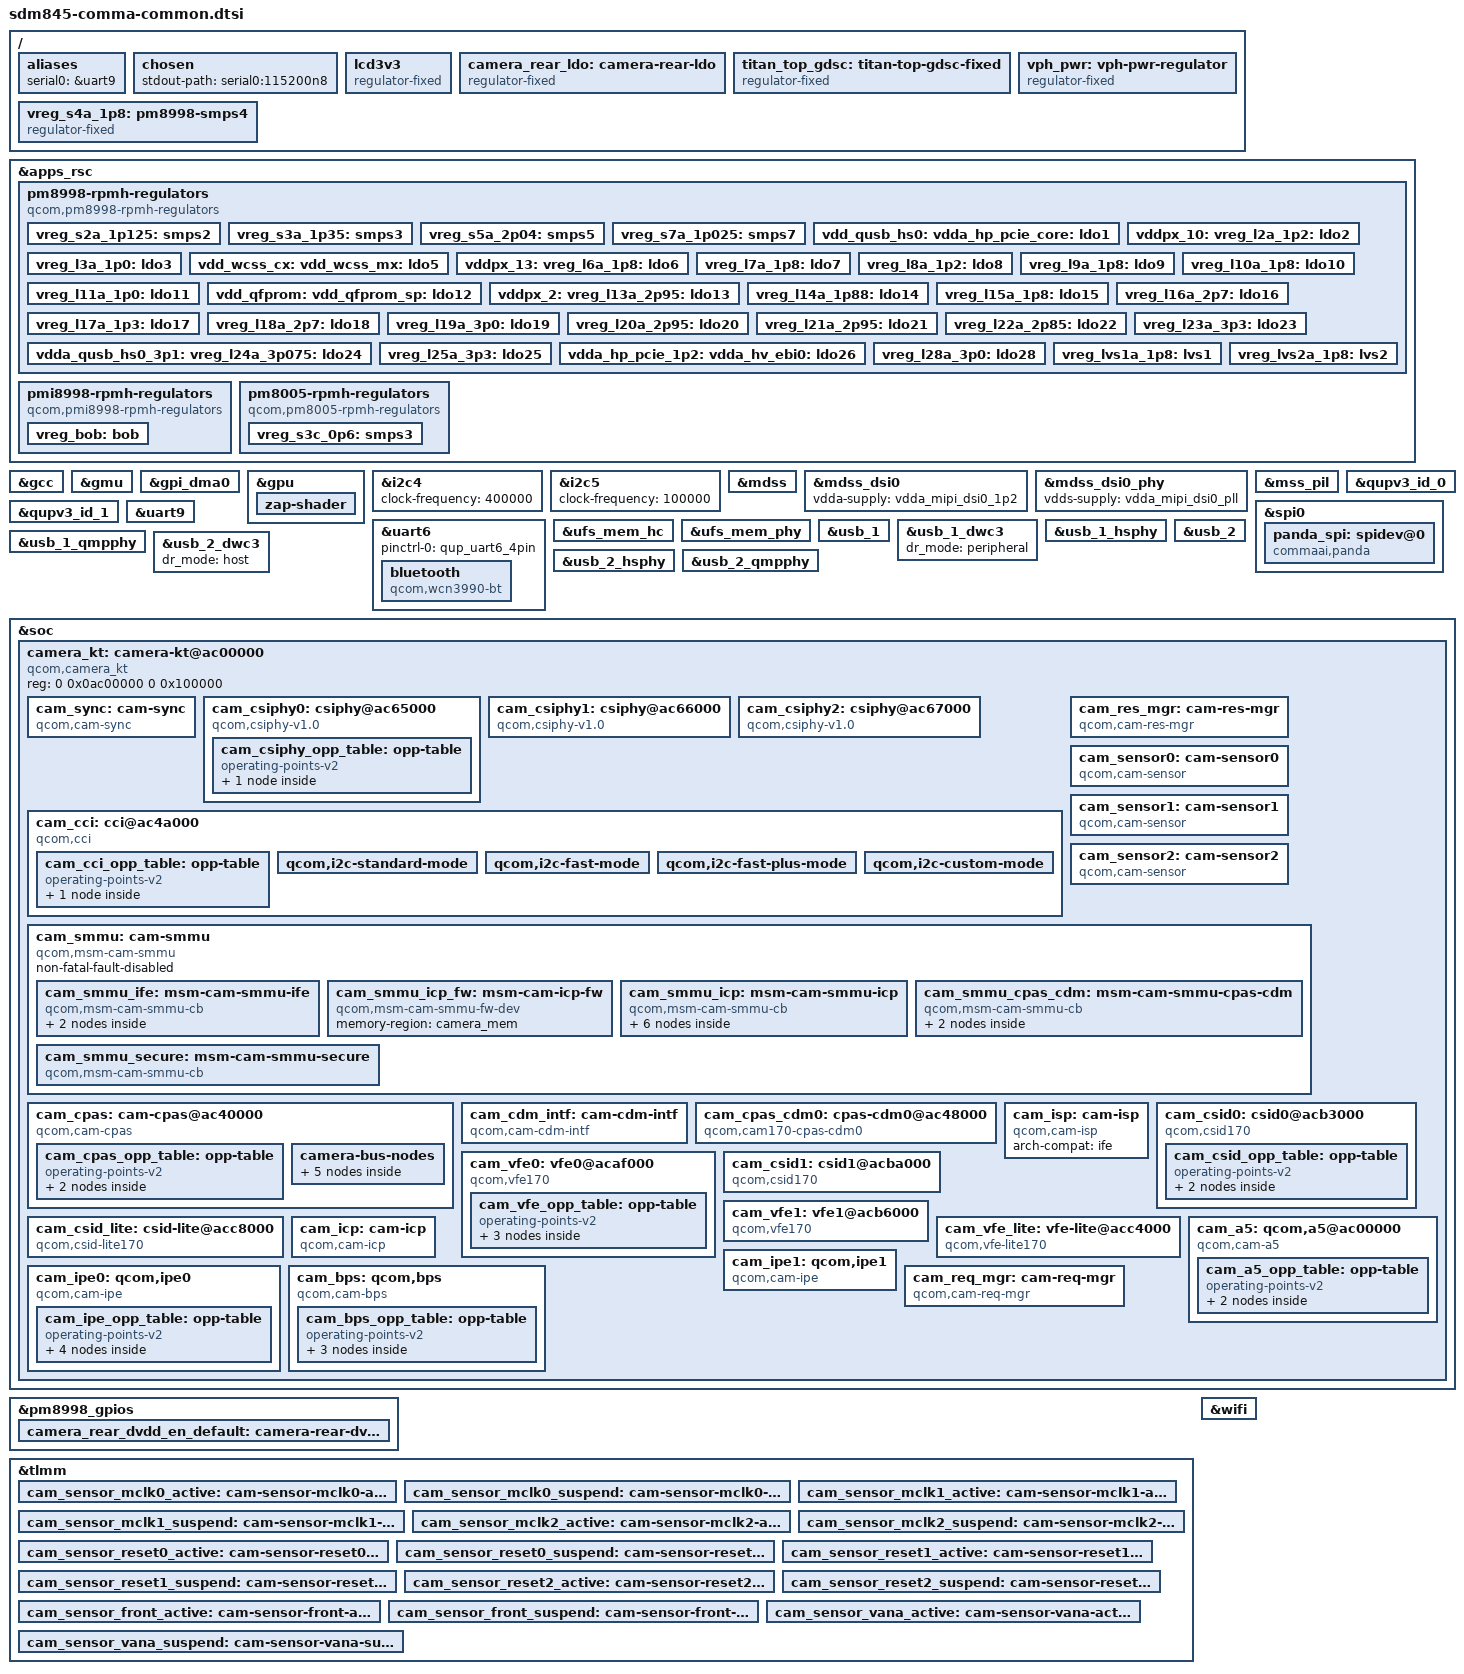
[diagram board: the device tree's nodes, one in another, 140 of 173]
/dts-v1/;

#include <dt-bindings/pinctrl/qcom,pmic-gpio.h>
#include <dt-bindings/regulator/qcom,rpmh-regulator.h>
#include <dt-bindings/power/qcom,rpmhpd.h>
#include "sdm845.dtsi"
#include "pm8998.dtsi"
#include "pmi8998.dtsi"

/ {
	aliases {
		serial0 = &uart9;
	};

	chosen {
		stdout-path = "serial0:115200n8";
	};

	lcd3v3: lcd3v3 {
		compatible = "regulator-fixed";
		regulator-name = "lcd3v3";
		regulator-min-microvolt = <3300000>;
		regulator-max-microvolt = <3300000>;
		gpio = <&pm8998_gpios 13 0>;
		regulator-boot-on;
	};

	camera_rear_ldo: camera-rear-ldo {
		compatible = "regulator-fixed";
		regulator-name = "camera_rear_ldo";
		regulator-min-microvolt = <1050000>;
		regulator-max-microvolt = <1050000>;
		regulator-enable-ramp-delay = <135>;
		gpio = <&pm8998_gpios 12 0>;
		enable-active-high;
		pinctrl-names = "default";
		pinctrl-0 = <&camera_rear_dvdd_en_default>;
	};

	titan_top_gdsc: titan-top-gdsc-fixed {
		compatible = "regulator-fixed";
		regulator-name = "titan_top_gdsc";
		regulator-always-on;
		regulator-boot-on;
	};

	vph_pwr: vph-pwr-regulator {
		compatible = "regulator-fixed";
		regulator-name = "vph_pwr";
		regulator-min-microvolt = <3700000>;
		regulator-max-microvolt = <3700000>;
	};

	/*
	 * Apparently RPMh does not provide support for PM8998 S4 because it
	 * is always-on; model it as a fixed regulator.
	 */
	vreg_s4a_1p8: pm8998-smps4 {
		compatible = "regulator-fixed";
		regulator-name = "vreg_s4a_1p8";

		regulator-min-microvolt = <1800000>;
		regulator-max-microvolt = <1800000>;

		regulator-always-on;
		regulator-boot-on;

		vin-supply = <&vph_pwr>;
	};
};

&apps_rsc {
	pm8998-rpmh-regulators {
		compatible = "qcom,pm8998-rpmh-regulators";
		qcom,pmic-id = "a";

		vdd-s1-supply = <&vph_pwr>;
		vdd-s2-supply = <&vph_pwr>;
		vdd-s3-supply = <&vph_pwr>;
		vdd-s4-supply = <&vph_pwr>;
		vdd-s5-supply = <&vph_pwr>;
		vdd-s6-supply = <&vph_pwr>;
		vdd-s7-supply = <&vph_pwr>;
		vdd-s8-supply = <&vph_pwr>;
		vdd-s9-supply = <&vph_pwr>;
		vdd-s10-supply = <&vph_pwr>;
		vdd-s11-supply = <&vph_pwr>;
		vdd-s12-supply = <&vph_pwr>;
		vdd-s13-supply = <&vph_pwr>;
		vdd-l1-l27-supply = <&vreg_s7a_1p025>;
		vdd-l2-l8-l17-supply = <&vreg_s3a_1p35>;
		vdd-l3-l11-supply = <&vreg_s7a_1p025>;
		vdd-l4-l5-supply = <&vreg_s7a_1p025>;
		vdd-l6-supply = <&vph_pwr>;
		vdd-l7-l12-l14-l15-supply = <&vreg_s5a_2p04>;
		vdd-l9-supply = <&vreg_bob>;
		vdd-l10-l23-l25-supply = <&vreg_bob>;
		vdd-l13-l19-l21-supply = <&vreg_bob>;
		vdd-l16-l28-supply = <&vreg_bob>;
		vdd-l18-l22-supply = <&vreg_bob>;
		vdd-l20-l24-supply = <&vreg_bob>;
		vdd-l26-supply = <&vreg_s3a_1p35>;
		vin-lvs-1-2-supply = <&vreg_s4a_1p8>;

		vreg_s2a_1p125: smps2 {
			regulator-min-microvolt = <1100000>;
			regulator-max-microvolt = <1100000>;
		};

		vreg_s3a_1p35: smps3 {
			regulator-min-microvolt = <1352000>;
			regulator-max-microvolt = <1352000>;
		};

		vreg_s5a_2p04: smps5 {
			regulator-min-microvolt = <1904000>;
			regulator-max-microvolt = <2040000>;
		};

		vreg_s7a_1p025: smps7 {
			regulator-min-microvolt = <900000>;
			regulator-max-microvolt = <1028000>;
		};

		vdd_qusb_hs0:
		vdda_hp_pcie_core:
		vdda_mipi_csi0_0p9:
		vdda_mipi_csi1_0p9:
		vdda_mipi_csi2_0p9:
		vdda_mipi_dsi0_pll:
		vdda_mipi_dsi1_pll:
		vdda_qlink_lv:
		vdda_qlink_lv_ck:
		vdda_qrefs_0p875:
		vdda_pcie_core:
		vdda_pll_cc_ebi01:
		vdda_pll_cc_ebi23:
		vdda_sp_sensor:
		vdda_ufs1_core:
		vdda_ufs2_core:
		vdda_usb1_ss_core:
		vdda_usb2_ss_core:
		vreg_l1a_0p875: ldo1 {
			regulator-min-microvolt = <880000>;
			regulator-max-microvolt = <880000>;
			regulator-initial-mode = <RPMH_REGULATOR_MODE_HPM>;
		};

		vddpx_10:
		vreg_l2a_1p2: ldo2 {
			regulator-min-microvolt = <1200000>;
			regulator-max-microvolt = <1200000>;
			regulator-initial-mode = <RPMH_REGULATOR_MODE_HPM>;
			regulator-always-on;
		};

		vreg_l3a_1p0: ldo3 {
			regulator-min-microvolt = <1000000>;
			regulator-max-microvolt = <1000000>;
			regulator-initial-mode = <RPMH_REGULATOR_MODE_HPM>;
		};

		vdd_wcss_cx:
		vdd_wcss_mx:
		vdda_wcss_pll:
		vreg_l5a_0p8: ldo5 {
			regulator-min-microvolt = <800000>;
			regulator-max-microvolt = <800000>;
			regulator-initial-mode = <RPMH_REGULATOR_MODE_HPM>;
		};

		vddpx_13:
		vreg_l6a_1p8: ldo6 {
			regulator-min-microvolt = <1856000>;
			regulator-max-microvolt = <1856000>;
			regulator-initial-mode = <RPMH_REGULATOR_MODE_HPM>;
		};

		vreg_l7a_1p8: ldo7 {
			regulator-min-microvolt = <1800000>;
			regulator-max-microvolt = <1800000>;
			regulator-initial-mode = <RPMH_REGULATOR_MODE_HPM>;
		};

		vreg_l8a_1p2: ldo8 {
			regulator-min-microvolt = <1200000>;
			regulator-max-microvolt = <1248000>;
			regulator-initial-mode = <RPMH_REGULATOR_MODE_HPM>;
		};

		vreg_l9a_1p8: ldo9 {
			regulator-min-microvolt = <1704000>;
			regulator-max-microvolt = <2928000>;
			regulator-initial-mode = <RPMH_REGULATOR_MODE_HPM>;
		};

		vreg_l10a_1p8: ldo10 {
			regulator-min-microvolt = <1704000>;
			regulator-max-microvolt = <2928000>;
			regulator-initial-mode = <RPMH_REGULATOR_MODE_HPM>;
		};

		vreg_l11a_1p0: ldo11 {
			regulator-min-microvolt = <1000000>;
			regulator-max-microvolt = <1048000>;
			regulator-initial-mode = <RPMH_REGULATOR_MODE_HPM>;
		};

		vdd_qfprom:
		vdd_qfprom_sp:
		vdda_apc1_cs_1p8:
		vdda_gfx_cs_1p8:
		vdda_qrefs_1p8:
		vdda_qusb_hs0_1p8:
		vddpx_11:
		vreg_l12a_1p8: ldo12 {
			regulator-min-microvolt = <1800000>;
			regulator-max-microvolt = <1800000>;
			regulator-initial-mode = <RPMH_REGULATOR_MODE_HPM>;
		};

		vddpx_2:
		vreg_l13a_2p95: ldo13 {
			regulator-min-microvolt = <1800000>;
			regulator-max-microvolt = <2960000>;
			regulator-initial-mode = <RPMH_REGULATOR_MODE_HPM>;
		};

		vreg_l14a_1p88: ldo14 {
			regulator-min-microvolt = <1800000>;
			regulator-max-microvolt = <1800000>;
			regulator-initial-mode = <RPMH_REGULATOR_MODE_HPM>;
		};

		vreg_l15a_1p8: ldo15 {
			regulator-min-microvolt = <1800000>;
			regulator-max-microvolt = <1800000>;
			regulator-initial-mode = <RPMH_REGULATOR_MODE_HPM>;
		};

		vreg_l16a_2p7: ldo16 {
			regulator-min-microvolt = <2704000>;
			regulator-max-microvolt = <2704000>;
			regulator-initial-mode = <RPMH_REGULATOR_MODE_HPM>;
		};

		vreg_l17a_1p3: ldo17 {
			regulator-min-microvolt = <1304000>;
			regulator-max-microvolt = <1304000>;
			regulator-initial-mode = <RPMH_REGULATOR_MODE_HPM>;
		};

		vreg_l18a_2p7: ldo18 {
			regulator-min-microvolt = <2704000>;
			regulator-max-microvolt = <2960000>;
			regulator-initial-mode = <RPMH_REGULATOR_MODE_HPM>;
		};

		vreg_l19a_3p0: ldo19 {
			regulator-min-microvolt = <2856000>;
			regulator-max-microvolt = <3104000>;
			regulator-initial-mode = <RPMH_REGULATOR_MODE_HPM>;
		};

		vreg_l20a_2p95: ldo20 {
			regulator-min-microvolt = <2704000>;
			regulator-max-microvolt = <2960000>;
			regulator-initial-mode = <RPMH_REGULATOR_MODE_HPM>;
		};

		vreg_l21a_2p95: ldo21 {
			regulator-min-microvolt = <2704000>;
			regulator-max-microvolt = <2960000>;
			regulator-initial-mode = <RPMH_REGULATOR_MODE_HPM>;
		};

		vreg_l22a_2p85: ldo22 {
			regulator-min-microvolt = <2864000>;
			regulator-max-microvolt = <3312000>;
			regulator-initial-mode = <RPMH_REGULATOR_MODE_HPM>;
		};

		vreg_l23a_3p3: ldo23 {
			regulator-min-microvolt = <3000000>;
			regulator-max-microvolt = <3312000>;
			regulator-initial-mode = <RPMH_REGULATOR_MODE_HPM>;
		};

		vdda_qusb_hs0_3p1:
		vreg_l24a_3p075: ldo24 {
			regulator-min-microvolt = <3088000>;
			regulator-max-microvolt = <3088000>;
			regulator-initial-mode = <RPMH_REGULATOR_MODE_HPM>;
		};

		vreg_l25a_3p3: ldo25 {
			regulator-min-microvolt = <3300000>;
			regulator-max-microvolt = <3312000>;
			regulator-initial-mode = <RPMH_REGULATOR_MODE_HPM>;
		};

		vdda_hp_pcie_1p2:
		vdda_hv_ebi0:
		vdda_hv_ebi1:
		vdda_hv_ebi2:
		vdda_hv_ebi3:
		vdda_mipi_csi_1p25:
		vdda_mipi_dsi0_1p2:
		vdda_mipi_dsi1_1p2:
		vdda_pcie_1p2:
		vdda_ufs1_1p2:
		vdda_ufs2_1p2:
		vdda_usb1_ss_1p2:
		vdda_usb2_ss_1p2:
		vreg_l26a_1p2: ldo26 {
			regulator-min-microvolt = <1200000>;
			regulator-max-microvolt = <1200000>;
			regulator-initial-mode = <RPMH_REGULATOR_MODE_HPM>;
		};

		vreg_l28a_3p0: ldo28 {
			regulator-min-microvolt = <2856000>;
			regulator-max-microvolt = <3008000>;
			regulator-initial-mode = <RPMH_REGULATOR_MODE_HPM>;
		};

		vreg_lvs1a_1p8: lvs1 {
			regulator-min-microvolt = <1800000>;
			regulator-max-microvolt = <1800000>;
		};

		vreg_lvs2a_1p8: lvs2 {
			regulator-min-microvolt = <1800000>;
			regulator-max-microvolt = <1800000>;
		};
	};

	pmi8998-rpmh-regulators {
		compatible = "qcom,pmi8998-rpmh-regulators";
		qcom,pmic-id = "b";

		vdd-bob-supply = <&vph_pwr>;

		vreg_bob: bob {
			regulator-min-microvolt = <3312000>;
			regulator-max-microvolt = <3600000>;
			regulator-initial-mode = <RPMH_REGULATOR_MODE_AUTO>;
			regulator-allow-bypass;
		};
	};

	pm8005-rpmh-regulators {
		compatible = "qcom,pm8005-rpmh-regulators";
		qcom,pmic-id = "c";

		vdd-s1-supply = <&vph_pwr>;
		vdd-s2-supply = <&vph_pwr>;
		vdd-s3-supply = <&vph_pwr>;
		vdd-s4-supply = <&vph_pwr>;

		vreg_s3c_0p6: smps3 {
			regulator-min-microvolt = <600000>;
			regulator-max-microvolt = <600000>;
		};
	};
};

&gcc {
	protected-clocks = <GCC_QSPI_CORE_CLK>,
			   <GCC_QSPI_CORE_CLK_SRC>,
			   <GCC_QSPI_CNOC_PERIPH_AHB_CLK>,
			   <GCC_LPASS_Q6_AXI_CLK>,
			   <GCC_LPASS_SWAY_CLK>;
};

&gmu {
	status = "okay";
};

&gpi_dma0 {
	status = "okay";
};

&gpu {
	status = "okay";

	zap-shader {
		memory-region = <&gpu_mem>;
		firmware-name = "qcom/sdm845/a630_zap.mbn";
	};
};

&i2c4 {
	status = "okay";
	clock-frequency = <400000>;
};

&i2c5 {
	status = "okay";
	clock-frequency = <100000>;
};

&mdss {
	status = "okay";
};

&mdss_dsi0 {
	status = "okay";
	vdda-supply = <&vdda_mipi_dsi0_1p2>;
};

&mdss_dsi0_phy {
	status = "okay";
	vdds-supply = <&vdda_mipi_dsi0_pll>;
};

&mss_pil {
	status = "okay";
	firmware-name = "qcom/sdm845/mba.mbn", "qcom/sdm845/modem_nm.mbn";
};

&qupv3_id_0 {
	status = "okay";
};

&qupv3_id_1 {
	status = "okay";
};

&spi0 {
	status = "okay";

	panda_spi: spidev@0 {
		compatible = "commaai,panda";
		spi-max-frequency = <50000000>;
		reg = <0>;
	};
};

&uart6 {
	status = "okay";
	pinctrl-0 = <&qup_uart6_4pin>;

	bluetooth {
		compatible = "qcom,wcn3990-bt";
		vddio-supply = <&vreg_s4a_1p8>;
		vddxo-supply = <&vreg_l7a_1p8>;
		vddrf-supply = <&vreg_l17a_1p3>;
		vddch0-supply = <&vreg_l25a_3p3>;
		max-speed = <3200000>;
	};
};

&uart9 {
	status = "okay";
};

&ufs_mem_hc {
	status = "okay";

	reset-gpios = <&tlmm 150 GPIO_ACTIVE_LOW>;

	vcc-supply = <&vreg_l20a_2p95>;
	vcc-max-microamp = <600000>;
};

&ufs_mem_phy {
	status = "okay";

	vdda-phy-supply = <&vdda_ufs1_core>;
	vdda-pll-supply = <&vdda_ufs1_1p2>;
	vdda-phy-max-microamp = <62900>;
	vdda-pll-max-microamp = <18300>;
};

&usb_1 {
	status = "okay";
};

&usb_1_dwc3 {
	dr_mode = "peripheral";
};

&usb_1_hsphy {
	status = "okay";

	vdd-supply = <&vdd_qusb_hs0>;
	vdda-phy-dpdm-supply = <&vdda_qusb_hs0_3p1>;
	vdda-pll-supply = <&vdda_qusb_hs0_1p8>;
};

&usb_1_qmpphy {
	status = "okay";

	vdda-phy-supply = <&vdda_usb1_ss_1p2>;
	vdda-pll-supply = <&vdda_usb1_ss_core>;
};

&usb_2 {
	status = "okay";
};

&usb_2_dwc3 {
	dr_mode = "host";
};

&usb_2_hsphy {
	status = "okay";

	vdd-supply = <&vdd_qusb_hs0>;
	vdda-pll-supply = <&vdda_qusb_hs0_1p8>;
	vdda-phy-dpdm-supply = <&vdda_qusb_hs0_3p1>;
};

&usb_2_qmpphy {
	status = "okay";

	vdda-phy-supply = <&vdda_usb2_ss_1p2>;
	vdda-pll-supply = <&vdda_usb2_ss_core>;
};

&soc {
	camera_kt: camera-kt@ac00000 {
		compatible = "qcom,camera_kt";
		reg = <0 0x0ac00000 0 0x100000>;
		#address-cells = <2>;
		#size-cells = <2>;
		ranges;
		status = "okay";

		cam_sync: cam-sync {
			compatible = "qcom,cam-sync";
			status = "okay";
		};

		cam_csiphy0: csiphy@ac65000 {
			compatible = "qcom,csiphy-v1.0", "qcom,csiphy";
			reg = <0 0x0ac65000 0 0x1000>;
			reg-names = "csiphy";
			reg-cam-base = <0x65000>;
			interrupts = <GIC_SPI 477 IRQ_TYPE_EDGE_RISING>;
			interrupt-names = "csiphy";
			cell-index = <0>;
			power-domains = <&clock_camcc TITAN_TOP_GDSC>;
			qcom,skip-probe-power-domain-cycle;
			gdscr-supply = <&titan_top_gdsc>;
			regulator-names = "gdscr";
			clocks = <&clock_camcc CAM_CC_CAMNOC_AXI_CLK>,
				 <&clock_camcc CAM_CC_SOC_AHB_CLK>,
				 <&clock_camcc CAM_CC_SLOW_AHB_CLK_SRC>,
				 <&clock_camcc CAM_CC_CPAS_AHB_CLK>,
				 <&clock_camcc CAM_CC_CPHY_RX_CLK_SRC>,
				 <&clock_camcc CAM_CC_CSIPHY0_CLK>,
				 <&clock_camcc CAM_CC_CSI0PHYTIMER_CLK_SRC>,
				 <&clock_camcc CAM_CC_CSI0PHYTIMER_CLK>;
			clock-names = "camnoc_axi_clk",
				      "soc_ahb_clk",
				      "slow_ahb_src_clk",
				      "cpas_ahb_clk",
				      "cphy_rx_clk_src",
				      "csiphy0_clk",
				      "csi0phytimer_clk_src",
				      "csi0phytimer_clk";
			clock-rates = <0 0 0 0 320000000 0 269333333 0>,
				      <0 0 0 0 384000000 0 269333333 0>;
			clock-cntl-level = "svs", "turbo";
			src-clock-name = "csi0phytimer_clk_src";
			operating-points-v2 = <&cam_csiphy_opp_table>;
			status = "okay";

			cam_csiphy_opp_table: opp-table {
				compatible = "operating-points-v2";

				opp-269333333 {
					opp-hz = /bits/ 64 <269333333>;
				};
			};
		};

		cam_csiphy1: csiphy@ac66000 {
			compatible = "qcom,csiphy-v1.0", "qcom,csiphy";
			reg = <0 0x0ac66000 0 0x1000>;
			reg-names = "csiphy";
			reg-cam-base = <0x66000>;
			interrupts = <GIC_SPI 478 IRQ_TYPE_EDGE_RISING>;
			interrupt-names = "csiphy";
			cell-index = <1>;
			power-domains = <&clock_camcc TITAN_TOP_GDSC>;
			qcom,skip-probe-power-domain-cycle;
			clocks = <&clock_camcc CAM_CC_CAMNOC_AXI_CLK>,
				 <&clock_camcc CAM_CC_SOC_AHB_CLK>,
				 <&clock_camcc CAM_CC_SLOW_AHB_CLK_SRC>,
				 <&clock_camcc CAM_CC_CPAS_AHB_CLK>,
				 <&clock_camcc CAM_CC_CPHY_RX_CLK_SRC>,
				 <&clock_camcc CAM_CC_CSIPHY1_CLK>,
				 <&clock_camcc CAM_CC_CSI1PHYTIMER_CLK_SRC>,
				 <&clock_camcc CAM_CC_CSI1PHYTIMER_CLK>;
			clock-names = "camnoc_axi_clk",
				      "soc_ahb_clk",
				      "slow_ahb_src_clk",
				      "cpas_ahb_clk",
				      "cphy_rx_clk_src",
				      "csiphy1_clk",
				      "csi1phytimer_clk_src",
				      "csi1phytimer_clk";
			clock-rates = <0 0 0 0 320000000 0 269333333 0>,
				      <0 0 0 0 384000000 0 269333333 0>;
			clock-cntl-level = "svs", "turbo";
			src-clock-name = "csi1phytimer_clk_src";
			operating-points-v2 = <&cam_csiphy_opp_table>;
			status = "okay";
		};

		cam_csiphy2: csiphy@ac67000 {
			compatible = "qcom,csiphy-v1.0", "qcom,csiphy";
			reg = <0 0x0ac67000 0 0x1000>;
			reg-names = "csiphy";
			reg-cam-base = <0x67000>;
			interrupts = <GIC_SPI 479 IRQ_TYPE_EDGE_RISING>;
			interrupt-names = "csiphy";
			cell-index = <2>;
			power-domains = <&clock_camcc TITAN_TOP_GDSC>;
			qcom,skip-probe-power-domain-cycle;
			clocks = <&clock_camcc CAM_CC_CAMNOC_AXI_CLK>,
				 <&clock_camcc CAM_CC_SOC_AHB_CLK>,
				 <&clock_camcc CAM_CC_SLOW_AHB_CLK_SRC>,
				 <&clock_camcc CAM_CC_CPAS_AHB_CLK>,
				 <&clock_camcc CAM_CC_CPHY_RX_CLK_SRC>,
				 <&clock_camcc CAM_CC_CSIPHY2_CLK>,
				 <&clock_camcc CAM_CC_CSI2PHYTIMER_CLK_SRC>,
				 <&clock_camcc CAM_CC_CSI2PHYTIMER_CLK>;
			clock-names = "camnoc_axi_clk",
				      "soc_ahb_clk",
				      "slow_ahb_src_clk",
				      "cpas_ahb_clk",
				      "cphy_rx_clk_src",
				      "csiphy2_clk",
				      "csi2phytimer_clk_src",
				      "csi2phytimer_clk";
			clock-rates = <0 0 0 0 320000000 0 269333333 0>,
				      <0 0 0 0 384000000 0 269333333 0>;
			clock-cntl-level = "svs", "turbo";
			src-clock-name = "csi2phytimer_clk_src";
			operating-points-v2 = <&cam_csiphy_opp_table>;
			status = "okay";
		};

		cam_cci: cci@ac4a000 {
			/delete-property/ assigned-clocks;
			/delete-property/ assigned-clock-rates;
			/delete-property/ #address-cells;
			/delete-property/ #size-cells;
			compatible = "qcom,cci";
			reg = <0 0x0ac4a000 0 0x4000>;
			reg-names = "cci";
			reg-cam-base = <0x4a000>;
			interrupts = <GIC_SPI 460 IRQ_TYPE_EDGE_RISING>;
			interrupt-names = "cci";
			cell-index = <0>;
			/*
			 * Vote the CX rail corner alongside the Titan GDSC. The
			 * downstream camera-kernel maps clock-cntl-level="lowsvs"
			 * to a CX LOW_SVS vote; mainline's dev_pm_opp_set_rate()
			 * path drops it (the OPP table carries only opp-hz), so CX
			 * sits at the MIN_SVS enable_corner floor and the OS04C10
			 * I2C transaction is marginal -> address NACK. Add CX as a
			 * second power-domain with a required-opps so genpd raises
			 * CX to LOW_SVS while the CCI block is powered.
			 */
			power-domains = <&clock_camcc TITAN_TOP_GDSC>,
					<&rpmhpd SDM845_CX>;
			power-domain-names = "titan", "cx";
			qcom,skip-probe-power-domain-cycle;
			clocks = <&clock_camcc CAM_CC_CAMNOC_AXI_CLK>,
				 <&clock_camcc CAM_CC_SOC_AHB_CLK>,
				 <&clock_camcc CAM_CC_SLOW_AHB_CLK_SRC>,
				 <&clock_camcc CAM_CC_CPAS_AHB_CLK>,
				 <&clock_camcc CAM_CC_CCI_CLK>,
				 <&clock_camcc CAM_CC_CCI_CLK_SRC>;
			clock-names = "camnoc_axi_clk",
				      "soc_ahb_clk",
				      "slow_ahb_src_clk",
				      "cpas_ahb_clk",
				      "cci_clk",
				      "cci_clk_src";
			clock-rates = <0 0 0 0 0 37500000>;
			clock-cntl-level = "lowsvs";
			src-clock-name = "cci_clk_src";
			operating-points-v2 = <&cam_cci_opp_table>;
			pinctrl-names = "cam_default", "cam_suspend";
			pinctrl-0 = <&cci0_default &cci1_default>;
			pinctrl-1 = <&cci0_sleep &cci1_sleep>;
			gpios = <&tlmm 17 0>,
				<&tlmm 18 0>,
				<&tlmm 19 0>,
				<&tlmm 20 0>;
			gpio-req-tbl-num = <0 1 2 3>;
			gpio-req-tbl-flags = <1 1 1 1>;
			gpio-req-tbl-label = "CCI_I2C_DATA0",
					     "CCI_I2C_CLK0",
					     "CCI_I2C_DATA1",
					     "CCI_I2C_CLK1";
			status = "okay";
			/delete-node/ i2c-bus@0;
			/delete-node/ i2c-bus@1;

			cam_cci_opp_table: opp-table {
				compatible = "operating-points-v2";

				opp-37500000 {
					opp-hz = /bits/ 64 <37500000>;
					/* raise CX to LOW_SVS while CCI is active */
					required-opps = <&rpmhpd_opp_low_svs>;
				};
			};

			qcom,i2c-standard-mode {
				hw-thigh = <201>;
				hw-tlow = <174>;
				hw-tsu-sto = <204>;
				hw-tsu-sta = <231>;
				hw-thd-dat = <22>;
				hw-thd-sta = <162>;
				hw-tbuf = <227>;
				hw-scl-stretch-en = <0>;
				hw-trdhld = <6>;
				hw-tsp = <3>;
				cci-clk-src = <37500000>;
			};

			qcom,i2c-fast-mode {
				hw-thigh = <38>;
				hw-tlow = <56>;
				hw-tsu-sto = <40>;
				hw-tsu-sta = <40>;
				hw-thd-dat = <22>;
				hw-thd-sta = <35>;
				hw-tbuf = <62>;
				hw-scl-stretch-en = <0>;
				hw-trdhld = <6>;
				hw-tsp = <3>;
				cci-clk-src = <37500000>;
			};

			qcom,i2c-fast-plus-mode {
				hw-thigh = <16>;
				hw-tlow = <22>;
				hw-tsu-sto = <17>;
				hw-tsu-sta = <18>;
				hw-thd-dat = <16>;
				hw-thd-sta = <15>;
				hw-tbuf = <24>;
				hw-scl-stretch-en = <0>;
				hw-trdhld = <3>;
				hw-tsp = <3>;
				cci-clk-src = <37500000>;
			};

			qcom,i2c-custom-mode {
				hw-thigh = <38>;
				hw-tlow = <56>;
				hw-tsu-sto = <40>;
				hw-tsu-sta = <40>;
				hw-thd-dat = <22>;
				hw-thd-sta = <35>;
				hw-tbuf = <62>;
				hw-scl-stretch-en = <1>;
				hw-trdhld = <6>;
				hw-tsp = <3>;
				cci-clk-src = <37500000>;
			};
		};

			cam_res_mgr: cam-res-mgr {
				compatible = "qcom,cam-res-mgr";
				gpios-shared = <560>;
				pinctrl-names = "default", "sleep";
				pinctrl-0 = <&cam_sensor_vana_active>;
				pinctrl-1 = <&cam_sensor_vana_suspend>;
				status = "okay";
			};

		cam_sensor0: cam-sensor0 {
			compatible = "qcom,cam-sensor";
			cell-index = <0>;
			csiphy-sd-index = <0>;
			sensor-position-roll = <180>;
			sensor-position-pitch = <0>;
			sensor-position-yaw = <0>;
			cam_vio-supply = <&vreg_lvs1a_1p8>;
			cam_vana-supply = <&vreg_bob>;
			cam_vdig-supply = <&camera_rear_ldo>;
			cam_clk-supply = <&titan_top_gdsc>;
			/*
			 * power-domains IS required on mainline: the MCLK branch
			 * (cam_cc_mclk0_clk) is gated by CAMCC under TITAN_TOP_GDSC,
			 * and clk_prepare_enable() returns -EBUSY unless the genpd
			 * is powered (pm_runtime_get_sync) before the MCLK step.
			 * Without it the MCLK enable fails and the power-up aborts
			 * before reset-deassert, leaving the sensor held in reset
			 * (I2C NACK). Patch 0028 defers the genpd enable to the MCLK
			 * step so it is on before clk_prepare_enable but not pulsed
			 * at the first (VIO) regulator step. Legacy 4.9 needs no
			 * power-domains because its 4.9 clk framework gated the MCLK
			 * branch via the cam_clk regulator instead.
			 */
			power-domains = <&clock_camcc TITAN_TOP_GDSC>;
			regulator-names = "cam_vio", "cam_vana", "cam_vdig", "cam_clk";
			rgltr-cntrl-support;
			rgltr-min-voltage = <0 3312000 1050000 0>;
			rgltr-max-voltage = <0 3600000 1050000 0>;
			rgltr-load-current = <0 80000 105000 0>;
			gpio-no-mux = <0>;
			pinctrl-names = "cam_default", "cam_suspend";
			pinctrl-0 = <&cam_sensor_mclk0_active
				     &cam_sensor_reset0_active>;
			pinctrl-1 = <&cam_sensor_mclk0_suspend
				     &cam_sensor_reset0_suspend>;
			gpios = <&tlmm 13 0>,
				<&tlmm 9 0>,
				<&tlmm 8 0>;
			gpio-reset = <1>;
			gpio-vana = <2>;
			gpio-req-tbl-num = <0 1 2>;
			gpio-req-tbl-flags = <1 0 0>;
			gpio-req-tbl-label = "CAMIF_MCLK0",
					     "CAM_RESET0",
					     "CAM_VANA0";
			sensor-mode = <0>;
			cci-master = <0>;
			clocks = <&clock_camcc CAM_CC_MCLK0_CLK>;
			clock-names = "cam_clk";
			clock-cntl-level = "turbo";
			clock-rates = <24000000>;
			status = "okay";
		};

		cam_sensor1: cam-sensor1 {
			compatible = "qcom,cam-sensor";
			cell-index = <1>;
			csiphy-sd-index = <1>;
			sensor-position-roll = <180>;
			sensor-position-pitch = <0>;
			sensor-position-yaw = <0>;
			cam_vio-supply = <&vreg_lvs1a_1p8>;
			cam_vana-supply = <&vreg_bob>;
			cam_vdig-supply = <&camera_rear_ldo>;
			cam_clk-supply = <&titan_top_gdsc>;
			/*
			 * power-domains IS required on mainline: the MCLK branch
			 * (cam_cc_mclk0_clk) is gated by CAMCC under TITAN_TOP_GDSC,
			 * and clk_prepare_enable() returns -EBUSY unless the genpd
			 * is powered (pm_runtime_get_sync) before the MCLK step.
			 * Without it the MCLK enable fails and the power-up aborts
			 * before reset-deassert, leaving the sensor held in reset
			 * (I2C NACK). Patch 0028 defers the genpd enable to the MCLK
			 * step so it is on before clk_prepare_enable but not pulsed
			 * at the first (VIO) regulator step. Legacy 4.9 needs no
			 * power-domains because its 4.9 clk framework gated the MCLK
			 * branch via the cam_clk regulator instead.
			 */
			power-domains = <&clock_camcc TITAN_TOP_GDSC>;
			regulator-names = "cam_vio", "cam_vana", "cam_vdig", "cam_clk";
			rgltr-cntrl-support;
			rgltr-min-voltage = <0 3312000 1050000 0>;
			rgltr-max-voltage = <0 3600000 1050000 0>;
			rgltr-load-current = <0 80000 105000 0>;
			gpio-no-mux = <0>;
			pinctrl-names = "cam_default", "cam_suspend";
			pinctrl-0 = <&cam_sensor_mclk1_active>;
			pinctrl-1 = <&cam_sensor_mclk1_suspend>;
			gpios = <&tlmm 14 0>,
				<&tlmm 7 0>,
				<&tlmm 8 0>;
			gpio-reset = <1>;
			gpio-vana = <2>;
			gpio-req-tbl-num = <0 1 2>;
			gpio-req-tbl-flags = <1 0 0>;
			gpio-req-tbl-label = "CAMIF_MCLK1",
					     "CAM_RESET1",
					     "CAM_VANA1";
			sensor-mode = <0>;
			cci-master = <0>;
			clocks = <&clock_camcc CAM_CC_MCLK1_CLK>;
			clock-names = "cam_clk";
			clock-cntl-level = "turbo";
			clock-rates = <24000000>;
			status = "okay";
		};

		cam_sensor2: cam-sensor2 {
			compatible = "qcom,cam-sensor";
			cell-index = <2>;
			csiphy-sd-index = <2>;
			sensor-position-roll = <180>;
			sensor-position-pitch = <0>;
			sensor-position-yaw = <0>;
			cam_vio-supply = <&vreg_lvs1a_1p8>;
			cam_vana-supply = <&vreg_bob>;
			cam_vdig-supply = <&camera_rear_ldo>;
			cam_clk-supply = <&titan_top_gdsc>;
			/*
			 * power-domains IS required on mainline: the MCLK branch
			 * (cam_cc_mclk0_clk) is gated by CAMCC under TITAN_TOP_GDSC,
			 * and clk_prepare_enable() returns -EBUSY unless the genpd
			 * is powered (pm_runtime_get_sync) before the MCLK step.
			 * Without it the MCLK enable fails and the power-up aborts
			 * before reset-deassert, leaving the sensor held in reset
			 * (I2C NACK). Patch 0028 defers the genpd enable to the MCLK
			 * step so it is on before clk_prepare_enable but not pulsed
			 * at the first (VIO) regulator step. Legacy 4.9 needs no
			 * power-domains because its 4.9 clk framework gated the MCLK
			 * branch via the cam_clk regulator instead.
			 */
			power-domains = <&clock_camcc TITAN_TOP_GDSC>;
			regulator-names = "cam_vio", "cam_vana", "cam_vdig", "cam_clk";
			rgltr-cntrl-support;
			rgltr-min-voltage = <0 3312000 1050000 0>;
			rgltr-max-voltage = <0 3600000 1050000 0>;
			rgltr-load-current = <0 80000 105000 0>;
			gpio-no-mux = <0>;
			pinctrl-names = "cam_default", "cam_suspend";
			pinctrl-0 = <&cam_sensor_mclk2_active
				     &cam_sensor_front_active>;
			pinctrl-1 = <&cam_sensor_mclk2_suspend
				     &cam_sensor_front_suspend>;
			gpios = <&tlmm 15 0>,
				<&tlmm 12 0>,
				<&tlmm 8 0>;
			gpio-reset = <1>;
			gpio-vana = <2>;
			gpio-req-tbl-num = <0 1 2>;
			gpio-req-tbl-flags = <1 0 0>;
			gpio-req-tbl-label = "CAMIF_MCLK2",
					     "CAM_RESET2",
					     "CAM_VANA2";
			sensor-mode = <0>;
			cci-master = <1>;
			clocks = <&clock_camcc CAM_CC_MCLK2_CLK>;
			clock-names = "cam_clk";
			clock-cntl-level = "turbo";
			clock-rates = <24000000>;
			status = "okay";
		};

		cam_smmu: cam-smmu {
			compatible = "qcom,msm-cam-smmu", "simple-bus";
			#address-cells = <2>;
			#size-cells = <2>;
			ranges;
			non-fatal-fault-disabled;
			status = "okay";

			cam_smmu_ife: msm-cam-smmu-ife {
				compatible = "qcom,msm-cam-smmu-cb";
				iommus = <&apps_smmu 0x808 0x0>,
					 <&apps_smmu 0x810 0x8>,
					 <&apps_smmu 0xc08 0x0>,
					 <&apps_smmu 0xc10 0x8>;
				cam-smmu-label = "ife";

				iova-mem-map {
					iova-mem-region-io {
						iova-region-name = "io";
						iova-region-start = <0x7400000>;
						iova-region-len = <0xd8c00000>;
						iova-region-id = <0x3>;
						status = "okay";
					};
				};
			};

			cam_smmu_icp_fw: msm-cam-icp-fw {
				compatible = "qcom,msm-cam-smmu-fw-dev";
				memory-region = <&camera_mem>;
				status = "okay";
			};

			cam_smmu_icp: msm-cam-smmu-icp {
				compatible = "qcom,msm-cam-smmu-cb";
				iommus = <&apps_smmu 0x107A 0x2>,
					 <&apps_smmu 0x1020 0x8>,
					 <&apps_smmu 0x1040 0x8>,
					 <&apps_smmu 0x1030 0x0>,
					 <&apps_smmu 0x1050 0x0>;
				cam-smmu-label = "icp";

				iova-mem-map {
					iova-mem-region-firmware {
						iova-region-name = "firmware";
						iova-region-start = <0x0>;
						iova-region-len = <0x500000>;
						iova-region-id = <0x0>;
						status = "okay";
					};

					iova-mem-region-shared {
						iova-region-name = "shared";
						iova-region-start = <0x7400000>;
						iova-region-len = <0x6400000>;
						iova-region-id = <0x1>;
						status = "okay";
					};

					iova-mem-region-secondary-heap {
						iova-region-name = "secheap";
						iova-region-start = <0xd800000>;
						iova-region-len = <0x100000>;
						iova-region-id = <0x4>;
						status = "okay";
					};

					iova-mem-region-io {
						iova-region-name = "io";
						iova-region-start = <0xda00000>;
						iova-region-len = <0xd2500000>;
						iova-region-id = <0x3>;
						status = "okay";
					};

					iova-mem-region-qdss {
						iova-region-name = "qdss";
						iova-region-start = <0xd900000>;
						iova-region-len = <0x100000>;
						iova-region-id = <0x5>;
						qdss-phy-addr = <0x16790000>;
						status = "okay";
					};
				};
			};

			cam_smmu_cpas_cdm: msm-cam-smmu-cpas-cdm {
				compatible = "qcom,msm-cam-smmu-cb";
				iommus = <&apps_smmu 0x1000 0x0>;
				cam-smmu-label = "cpas-cdm0", "cpas-cdm";

				iova-mem-map {
					iova-mem-region-io {
						iova-region-name = "io";
						iova-region-start = <0x7400000>;
						iova-region-len = <0xd8c00000>;
						iova-region-id = <0x3>;
						status = "okay";
					};
				};
			};

			cam_smmu_secure: msm-cam-smmu-secure {
				compatible = "qcom,msm-cam-smmu-cb";
				cam-smmu-label = "cam-secure";
				qcom,secure-cb;
				status = "okay";
			};
		};

		cam_cpas: cam-cpas@ac40000 {
			compatible = "qcom,cam-cpas";
			reg = <0 0x0ac40000 0 0x1000>,
			      <0 0x0ac42000 0 0x5000>;
			reg-names = "cam_cpas_top", "cam_camnoc";
			reg-cam-base = <0x40000 0x42000>;
			interrupts = <GIC_SPI 459 IRQ_TYPE_LEVEL_HIGH>;
			interrupt-names = "cpas_camnoc";
			label = "cpas";
			cell-index = <0>;
			arch-compat = "cpas_top";
			qcom,cpas-hw-ver = <0x170110>;
			camnoc-axi-min-ib-bw = <3000000000>;
			power-domains = <&clock_camcc TITAN_TOP_GDSC>;
			camss-vdd-supply = <&titan_top_gdsc>;
			regulator-names = "camss-vdd";
			clocks = <&gcc GCC_CAMERA_AHB_CLK>,
				 <&gcc GCC_CAMERA_AXI_CLK>,
				 <&clock_camcc CAM_CC_SOC_AHB_CLK>,
				 <&clock_camcc CAM_CC_SLOW_AHB_CLK_SRC>,
				 <&clock_camcc CAM_CC_CPAS_AHB_CLK>,
				 <&clock_camcc CAM_CC_CAMNOC_AXI_CLK>;
			clock-names = "gcc_ahb_clk", "gcc_axi_clk",
				      "soc_ahb_clk", "slow_ahb_clk_src",
				      "cpas_ahb_clk", "camnoc_axi_clk";
			src-clock-name = "slow_ahb_clk_src";
			clock-rates = <0 0 0 0 0 0>,
				      <0 0 0 19200000 0 0>,
				      <0 0 0 80000000 0 0>,
				      <0 0 0 80000000 0 0>,
				      <0 0 0 80000000 0 0>,
				      <0 0 0 80000000 0 0>,
				      <0 0 0 80000000 0 0>;
			clock-cntl-level = "suspend", "minsvs", "lowsvs",
					   "svs", "svs_l1", "nominal",
					   "turbo";
			operating-points-v2 = <&cam_cpas_opp_table>;
			interconnects =
				<&gladiator_noc MASTER_APPSS_PROC QCOM_ICC_TAG_ALWAYS
				 &config_noc SLAVE_CAMERA_CFG QCOM_ICC_TAG_ALWAYS>,
				<&mmss_noc MASTER_CAMNOC_HF0 QCOM_ICC_TAG_ALWAYS
				 &mem_noc SLAVE_EBI1 QCOM_ICC_TAG_ALWAYS>,
				<&mmss_noc MASTER_CAMNOC_SF QCOM_ICC_TAG_ALWAYS
				 &mem_noc SLAVE_EBI1 QCOM_ICC_TAG_ALWAYS>;
			interconnect-names = "cam_ahb", "cam_hf_0", "cam_sf_0";
			cam-ahb-num-cases = <8>;
			cam-ahb-bw-KBps = <0 0>, <0 300000>, <0 300000>,
					   <0 300000>, <0 300000>, <0 300000>,
					   <0 300000>, <0 300000>;
			client-id-based;
			client-names = "csiphy0", "csiphy1", "csiphy2",
				       "cci0", "csid0", "csid1", "csid2",
				       "ife0", "ife1", "ife2", "ipe0", "ipe1",
				       "cam-cdm-intf0", "cpas-cdm0",
				       "bps0", "icp0";
			status = "okay";

			cam_cpas_opp_table: opp-table {
				compatible = "operating-points-v2";

				opp-19200000 {
					opp-hz = /bits/ 64 <19200000>;
				};

				opp-80000000 {
					opp-hz = /bits/ 64 <80000000>;
				};
			};

			camera-bus-nodes {
				level0-nodes {
					level-index = <0>;

					cpas_hf_axi: cam-hf-axi {
						cell-index = <0>;
						node-name = "cam-hf-axi";
						ib-bw-voting-needed;
						qcom,axi-port-mnoc {
							interconnect-names = "cam_hf_0";
							interconnects =
								<&mmss_noc MASTER_CAMNOC_HF0 QCOM_ICC_TAG_ALWAYS
								 &mem_noc SLAVE_EBI1 QCOM_ICC_TAG_ALWAYS>;
						};
					};

					cpas_sf_axi: cam-sf-axi {
						cell-index = <1>;
						node-name = "cam-sf-axi";
						qcom,axi-port-mnoc {
							interconnect-names = "cam_sf_0";
							interconnects =
								<&mmss_noc MASTER_CAMNOC_SF QCOM_ICC_TAG_ALWAYS
								 &mem_noc SLAVE_EBI1 QCOM_ICC_TAG_ALWAYS>;
						};
					};
				};
			};
		};

		cam_cdm_intf: cam-cdm-intf {
			compatible = "qcom,cam-cdm-intf";
			cell-index = <0>;
			label = "cam-cdm-intf";
			num-hw-cdm = <1>;
			cdm-client-names = "vfe";
			status = "okay";
		};

		cam_cpas_cdm0: cpas-cdm0@ac48000 {
			compatible = "qcom,cam170-cpas-cdm0";
			reg = <0 0x0ac48000 0 0x1000>;
			reg-names = "cpas-cdm";
			reg-cam-base = <0x48000>;
			interrupts = <GIC_SPI 461 IRQ_TYPE_EDGE_RISING>;
			interrupt-names = "cpas-cdm";
			label = "cpas-cdm";
			cell-index = <0>;
			power-domains = <&clock_camcc TITAN_TOP_GDSC>;
			qcom,skip-probe-power-domain-cycle;
			clocks = <&gcc GCC_CAMERA_AHB_CLK>,
				 <&gcc GCC_CAMERA_AXI_CLK>,
				 <&clock_camcc CAM_CC_SOC_AHB_CLK>,
				 <&clock_camcc CAM_CC_CPAS_AHB_CLK>,
				 <&clock_camcc CAM_CC_CAMNOC_AXI_CLK>;
			clock-names = "gcc_camera_ahb",
				      "gcc_camera_axi",
				      "cam_cc_soc_ahb_clk",
				      "cam_cc_cpas_ahb_clk",
				      "cam_cc_camnoc_axi_clk";
			clock-rates = <0 0 0 0 0>;
			clock-cntl-level = "svs";
			cdm-client-names = "ife", "ife3";
			status = "okay";
		};

		cam_isp: cam-isp {
			compatible = "qcom,cam-isp";
			arch-compat = "ife";
			status = "okay";
		};

		cam_csid0: csid0@acb3000 {
			compatible = "qcom,csid170";
			reg = <0 0x0acb3000 0 0x1000>;
			reg-names = "csid";
			reg-cam-base = <0xb3000>;
			interrupts = <GIC_SPI 464 IRQ_TYPE_EDGE_RISING>;
			interrupt-names = "csid";
			cell-index = <0>;
			power-domains = <&clock_camcc IFE_0_GDSC>;
			qcom,skip-probe-power-domain-cycle;
			clocks = <&gcc GCC_CAMERA_AHB_CLK>,
				 <&gcc GCC_CAMERA_AXI_CLK>,
				 <&clock_camcc CAM_CC_SOC_AHB_CLK>,
				 <&clock_camcc CAM_CC_CPAS_AHB_CLK>,
				 <&clock_camcc CAM_CC_SLOW_AHB_CLK_SRC>,
				 <&clock_camcc CAM_CC_IFE_0_CSID_CLK>,
				 <&clock_camcc CAM_CC_IFE_0_CSID_CLK_SRC>,
				 <&clock_camcc CAM_CC_IFE_0_CPHY_RX_CLK>,
				 <&clock_camcc CAM_CC_CPHY_RX_CLK_SRC>,
				 <&clock_camcc CAM_CC_IFE_0_CLK>,
				 <&clock_camcc CAM_CC_IFE_0_CLK_SRC>,
				 <&clock_camcc CAM_CC_CAMNOC_AXI_CLK>,
				 <&clock_camcc CAM_CC_IFE_0_AXI_CLK>;
			clock-names = "camera_ahb",
				      "camera_axi",
				      "soc_ahb_clk",
				      "cpas_ahb_clk",
				      "slow_ahb_clk_src",
				      "ife_csid_clk",
				      "ife_csid_clk_src",
				      "ife_cphy_rx_clk",
				      "cphy_rx_clk_src",
				      "ife_clk",
				      "ife_clk_src",
				      "camnoc_axi_clk",
				      "ife_axi_clk";
			clock-rates = <0 0 0 0 0 0 384000000 0 0 0 404000000 0 0>,
				      <0 0 0 0 0 0 538000000 0 0 0 600000000 0 0>;
			clock-cntl-level = "svs", "turbo";
			src-clock-name = "ife_csid_clk_src";
			operating-points-v2 = <&cam_csid_opp_table>;
			clock-control-debugfs = "true";
			status = "okay";

			cam_csid_opp_table: opp-table {
				compatible = "operating-points-v2";

				opp-384000000 {
					opp-hz = /bits/ 64 <384000000>;
				};

				opp-538000000 {
					opp-hz = /bits/ 64 <538000000>;
				};
			};
		};

		cam_vfe0: vfe0@acaf000 {
			compatible = "qcom,vfe170";
			reg = <0 0x0acaf000 0 0x4000>;
			reg-names = "ife";
			reg-cam-base = <0xaf000>;
			interrupts = <GIC_SPI 465 IRQ_TYPE_EDGE_RISING>;
			interrupt-names = "ife";
			cell-index = <0>;
			power-domains = <&clock_camcc IFE_0_GDSC>;
			qcom,skip-probe-power-domain-cycle;
			clocks = <&gcc GCC_CAMERA_AHB_CLK>,
				 <&gcc GCC_CAMERA_AXI_CLK>,
				 <&clock_camcc CAM_CC_SOC_AHB_CLK>,
				 <&clock_camcc CAM_CC_CPAS_AHB_CLK>,
				 <&clock_camcc CAM_CC_SLOW_AHB_CLK_SRC>,
				 <&clock_camcc CAM_CC_IFE_0_CLK>,
				 <&clock_camcc CAM_CC_IFE_0_CLK_SRC>,
				 <&clock_camcc CAM_CC_CAMNOC_AXI_CLK>,
				 <&clock_camcc CAM_CC_IFE_0_AXI_CLK>;
			clock-names = "camera_ahb",
				      "camera_axi",
				      "soc_ahb_clk",
				      "cpas_ahb_clk",
				      "slow_ahb_clk_src",
				      "ife_clk",
				      "ife_clk_src",
				      "camnoc_axi_clk",
				      "ife_axi_clk";
			clock-rates = <0 0 0 0 0 0 404000000 0 0>,
				      <0 0 0 0 0 0 480000000 0 0>,
				      <0 0 0 0 0 0 600000000 0 0>;
			clock-cntl-level = "svs", "svs_l1", "turbo";
			src-clock-name = "ife_clk_src";
			operating-points-v2 = <&cam_vfe_opp_table>;
			clock-control-debugfs = "true";
			clock-names-option = "ife_dsp_clk";
			clocks-option = <&clock_camcc CAM_CC_IFE_0_DSP_CLK>;
			clock-rates-option = <600000000>;
			status = "okay";

			cam_vfe_opp_table: opp-table {
				compatible = "operating-points-v2";

				opp-404000000 {
					opp-hz = /bits/ 64 <404000000>;
				};

				opp-480000000 {
					opp-hz = /bits/ 64 <480000000>;
				};

				opp-600000000 {
					opp-hz = /bits/ 64 <600000000>;
				};
			};
		};

		cam_csid1: csid1@acba000 {
			compatible = "qcom,csid170";
			reg = <0 0x0acba000 0 0x1000>;
			reg-names = "csid";
			reg-cam-base = <0xba000>;
			interrupts = <GIC_SPI 466 IRQ_TYPE_EDGE_RISING>;
			interrupt-names = "csid";
			cell-index = <1>;
			power-domains = <&clock_camcc IFE_1_GDSC>;
			qcom,skip-probe-power-domain-cycle;
			clocks = <&gcc GCC_CAMERA_AHB_CLK>,
				 <&gcc GCC_CAMERA_AXI_CLK>,
				 <&clock_camcc CAM_CC_SOC_AHB_CLK>,
				 <&clock_camcc CAM_CC_CPAS_AHB_CLK>,
				 <&clock_camcc CAM_CC_SLOW_AHB_CLK_SRC>,
				 <&clock_camcc CAM_CC_IFE_1_CSID_CLK>,
				 <&clock_camcc CAM_CC_IFE_1_CSID_CLK_SRC>,
				 <&clock_camcc CAM_CC_IFE_1_CPHY_RX_CLK>,
				 <&clock_camcc CAM_CC_CPHY_RX_CLK_SRC>,
				 <&clock_camcc CAM_CC_IFE_1_CLK>,
				 <&clock_camcc CAM_CC_IFE_1_CLK_SRC>,
				 <&clock_camcc CAM_CC_CAMNOC_AXI_CLK>,
				 <&clock_camcc CAM_CC_IFE_1_AXI_CLK>;
			clock-names = "camera_ahb",
				      "camera_axi",
				      "soc_ahb_clk",
				      "cpas_ahb_clk",
				      "slow_ahb_clk_src",
				      "ife_csid_clk",
				      "ife_csid_clk_src",
				      "ife_cphy_rx_clk",
				      "cphy_rx_clk_src",
				      "ife_clk",
				      "ife_clk_src",
				      "camnoc_axi_clk",
				      "ife_axi_clk";
			clock-rates = <0 0 0 0 0 0 384000000 0 0 0 404000000 0 0>,
				      <0 0 0 0 0 0 538000000 0 0 0 600000000 0 0>;
			clock-cntl-level = "svs", "turbo";
			src-clock-name = "ife_csid_clk_src";
			operating-points-v2 = <&cam_csid_opp_table>;
			clock-control-debugfs = "true";
			status = "okay";
		};

		cam_vfe1: vfe1@acb6000 {
			compatible = "qcom,vfe170";
			reg = <0 0x0acb6000 0 0x4000>;
			reg-names = "ife";
			reg-cam-base = <0xb6000>;
			interrupts = <GIC_SPI 467 IRQ_TYPE_EDGE_RISING>;
			interrupt-names = "ife";
			cell-index = <1>;
			power-domains = <&clock_camcc IFE_1_GDSC>;
			qcom,skip-probe-power-domain-cycle;
			clocks = <&gcc GCC_CAMERA_AHB_CLK>,
				 <&gcc GCC_CAMERA_AXI_CLK>,
				 <&clock_camcc CAM_CC_SOC_AHB_CLK>,
				 <&clock_camcc CAM_CC_CPAS_AHB_CLK>,
				 <&clock_camcc CAM_CC_SLOW_AHB_CLK_SRC>,
				 <&clock_camcc CAM_CC_IFE_1_CLK>,
				 <&clock_camcc CAM_CC_IFE_1_CLK_SRC>,
				 <&clock_camcc CAM_CC_CAMNOC_AXI_CLK>,
				 <&clock_camcc CAM_CC_IFE_1_AXI_CLK>;
			clock-names = "camera_ahb",
				      "camera_axi",
				      "soc_ahb_clk",
				      "cpas_ahb_clk",
				      "slow_ahb_clk_src",
				      "ife_clk",
				      "ife_clk_src",
				      "camnoc_axi_clk",
				      "ife_axi_clk";
			clock-rates = <0 0 0 0 0 0 404000000 0 0>,
				      <0 0 0 0 0 0 480000000 0 0>,
				      <0 0 0 0 0 0 600000000 0 0>;
			clock-cntl-level = "svs", "svs_l1", "turbo";
			src-clock-name = "ife_clk_src";
			operating-points-v2 = <&cam_vfe_opp_table>;
			clock-control-debugfs = "true";
			clock-names-option = "ife_dsp_clk";
			clocks-option = <&clock_camcc CAM_CC_IFE_1_DSP_CLK>;
			clock-rates-option = <600000000>;
			status = "okay";
		};

		cam_csid_lite: csid-lite@acc8000 {
			compatible = "qcom,csid-lite170";
			reg = <0 0x0acc8000 0 0x1000>;
			reg-names = "csid-lite";
			reg-cam-base = <0xc8000>;
			interrupts = <GIC_SPI 468 IRQ_TYPE_EDGE_RISING>;
			interrupt-names = "csid-lite";
			cell-index = <2>;
			power-domains = <&clock_camcc TITAN_TOP_GDSC>;
			qcom,skip-probe-power-domain-cycle;
			clocks = <&gcc GCC_CAMERA_AHB_CLK>,
				 <&gcc GCC_CAMERA_AXI_CLK>,
				 <&clock_camcc CAM_CC_SOC_AHB_CLK>,
				 <&clock_camcc CAM_CC_CPAS_AHB_CLK>,
				 <&clock_camcc CAM_CC_SLOW_AHB_CLK_SRC>,
				 <&clock_camcc CAM_CC_IFE_LITE_CSID_CLK>,
				 <&clock_camcc CAM_CC_IFE_LITE_CSID_CLK_SRC>,
				 <&clock_camcc CAM_CC_IFE_LITE_CPHY_RX_CLK>,
				 <&clock_camcc CAM_CC_CPHY_RX_CLK_SRC>,
				 <&clock_camcc CAM_CC_IFE_LITE_CLK>,
				 <&clock_camcc CAM_CC_IFE_LITE_CLK_SRC>,
				 <&clock_camcc CAM_CC_CAMNOC_AXI_CLK>;
			clock-names = "camera_ahb",
				      "camera_axi",
				      "soc_ahb_clk",
				      "cpas_ahb_clk",
				      "slow_ahb_clk_src",
				      "ife_csid_clk",
				      "ife_csid_clk_src",
				      "ife_cphy_rx_clk",
				      "cphy_rx_clk_src",
				      "ife_clk",
				      "ife_clk_src",
				      "camnoc_axi_clk";
			clock-rates = <0 0 0 0 0 0 384000000 0 0 0 404000000 0>,
				      <0 0 0 0 0 0 538000000 0 0 0 600000000 0>;
			clock-cntl-level = "svs", "turbo";
			src-clock-name = "ife_csid_clk_src";
			operating-points-v2 = <&cam_csid_opp_table>;
			clock-control-debugfs = "true";
			status = "okay";
		};

		cam_vfe_lite: vfe-lite@acc4000 {
			compatible = "qcom,vfe-lite170";
			reg = <0 0x0acc4000 0 0x4000>;
			reg-names = "ife-lite";
			reg-cam-base = <0xc4000>;
			interrupts = <GIC_SPI 469 IRQ_TYPE_EDGE_RISING>;
			interrupt-names = "ife-lite";
			cell-index = <2>;
			power-domains = <&clock_camcc TITAN_TOP_GDSC>;
			qcom,skip-probe-power-domain-cycle;
			clocks = <&gcc GCC_CAMERA_AHB_CLK>,
				 <&gcc GCC_CAMERA_AXI_CLK>,
				 <&clock_camcc CAM_CC_SOC_AHB_CLK>,
				 <&clock_camcc CAM_CC_CPAS_AHB_CLK>,
				 <&clock_camcc CAM_CC_SLOW_AHB_CLK_SRC>,
				 <&clock_camcc CAM_CC_IFE_LITE_CLK>,
				 <&clock_camcc CAM_CC_IFE_LITE_CLK_SRC>,
				 <&clock_camcc CAM_CC_CAMNOC_AXI_CLK>;
			clock-names = "camera_ahb",
				      "camera_axi",
				      "soc_ahb_clk",
				      "cpas_ahb_clk",
				      "slow_ahb_clk_src",
				      "ife_clk",
				      "ife_clk_src",
				      "camnoc_axi_clk";
			clock-rates = <0 0 0 0 0 0 404000000 0>,
				      <0 0 0 0 0 0 480000000 0>,
				      <0 0 0 0 0 0 600000000 0>;
			clock-cntl-level = "svs", "svs_l1", "turbo";
			src-clock-name = "ife_clk_src";
			operating-points-v2 = <&cam_vfe_opp_table>;
			clock-control-debugfs = "true";
			status = "okay";
		};

		cam_icp: cam-icp {
			compatible = "qcom,cam-icp";
			compat-hw-name = "qcom,a5", "qcom,ipe0",
					 "qcom,ipe1", "qcom,bps";
			num-a5 = <1>;
			num-ipe = <2>;
			num-bps = <1>;
			icp_pc_en;
			status = "okay";
		};

		cam_a5: qcom,a5@ac00000 {
			compatible = "qcom,cam-a5";
			reg = <0 0x0ac00000 0 0x6000>,
			      <0 0x0ac10000 0 0x8000>,
			      <0 0x0ac18000 0 0x3000>;
			reg-names = "a5_qgic", "a5_sierra", "a5_csr";
			reg-cam-base = <0x00000 0x10000 0x18000>;
			interrupts = <GIC_SPI 463 IRQ_TYPE_EDGE_RISING>;
			interrupt-names = "a5";
			cell-index = <0>;
			power-domains = <&clock_camcc TITAN_TOP_GDSC>;
			qcom,skip-probe-power-domain-cycle;
			clocks = <&gcc GCC_CAMERA_AHB_CLK>,
				 <&gcc GCC_CAMERA_AXI_CLK>,
				 <&clock_camcc CAM_CC_FAST_AHB_CLK_SRC>,
				 <&clock_camcc CAM_CC_SOC_AHB_CLK>,
				 <&clock_camcc CAM_CC_CPAS_AHB_CLK>,
				 <&clock_camcc CAM_CC_CAMNOC_AXI_CLK>,
				 <&clock_camcc CAM_CC_ICP_APB_CLK>,
				 <&clock_camcc CAM_CC_ICP_ATB_CLK>,
				 <&clock_camcc CAM_CC_ICP_CLK>,
				 <&clock_camcc CAM_CC_ICP_CLK_SRC>,
				 <&clock_camcc CAM_CC_ICP_CTI_CLK>,
				 <&clock_camcc CAM_CC_ICP_TS_CLK>;
			clock-names = "gcc_cam_ahb_clk",
				      "gcc_cam_axi_clk",
				      "soc_fast_ahb",
				      "soc_ahb_clk",
				      "cpas_ahb_clk",
				      "camnoc_axi_clk",
				      "icp_apb_clk",
				      "icp_atb_clk",
				      "icp_clk",
				      "icp_clk_src",
				      "icp_cti_clk",
				      "icp_ts_clk";
			clock-rates = <0 0 200000000 0 0 0 0 0 0 400000000 0 0>,
				      <0 0 200000000 0 0 0 0 0 0 600000000 0 0>;
			clock-cntl-level = "svs", "turbo";
			src-clock-name = "icp_clk_src";
			operating-points-v2 = <&cam_a5_opp_table>;
			fw_name = "CAMERA_ICP.elf";
			ubwc-cfg = <0x7b 0x1ef>;
			status = "okay";

			cam_a5_opp_table: opp-table {
				compatible = "operating-points-v2";

				opp-400000000 {
					opp-hz = /bits/ 64 <400000000>;
				};

				opp-600000000 {
					opp-hz = /bits/ 64 <600000000>;
				};
			};
		};

		cam_ipe0: qcom,ipe0 {
			compatible = "qcom,cam-ipe";
			reg = <0 0x0ac87000 0 0x3000>;
			reg-names = "ipe0_top";
			reg-cam-base = <0x87000>;
			cell-index = <0>;
			clocks = <&clock_camcc CAM_CC_IPE_0_AHB_CLK>,
				 <&clock_camcc CAM_CC_IPE_0_AREG_CLK>,
				 <&clock_camcc CAM_CC_IPE_0_AXI_CLK>,
				 <&clock_camcc CAM_CC_IPE_0_CLK>,
				 <&clock_camcc CAM_CC_IPE_0_CLK_SRC>;
			clock-names = "ipe_0_ahb_clk",
				      "ipe_0_areg_clk",
				      "ipe_0_axi_clk",
				      "ipe_0_clk",
				      "ipe_0_clk_src";
			clock-rates = <0 0 0 0 404000000>,
				      <0 0 0 0 480000000>,
				      <0 0 0 0 538000000>,
				      <0 0 0 0 600000000>;
			clock-cntl-level = "svs", "svs_l1", "nominal",
					   "turbo";
			power-domains = <&clock_camcc IPE_0_GDSC>;
			qcom,skip-probe-power-domain-cycle;
			src-clock-name = "ipe_0_clk_src";
			operating-points-v2 = <&cam_ipe_opp_table>;
			clock-control-debugfs = "true";
			status = "okay";

			cam_ipe_opp_table: opp-table {
				compatible = "operating-points-v2";

				opp-404000000 {
					opp-hz = /bits/ 64 <404000000>;
				};

				opp-480000000 {
					opp-hz = /bits/ 64 <480000000>;
				};

				opp-538000000 {
					opp-hz = /bits/ 64 <538000000>;
				};

				opp-600000000 {
					opp-hz = /bits/ 64 <600000000>;
				};
			};
		};

		cam_ipe1: qcom,ipe1 {
			compatible = "qcom,cam-ipe";
			reg = <0 0x0ac91000 0 0x3000>;
			reg-names = "ipe1_top";
			reg-cam-base = <0x91000>;
			cell-index = <1>;
			clocks = <&clock_camcc CAM_CC_IPE_1_AHB_CLK>,
				 <&clock_camcc CAM_CC_IPE_1_AREG_CLK>,
				 <&clock_camcc CAM_CC_IPE_1_AXI_CLK>,
				 <&clock_camcc CAM_CC_IPE_1_CLK>,
				 <&clock_camcc CAM_CC_IPE_1_CLK_SRC>;
			clock-names = "ipe_1_ahb_clk",
				      "ipe_1_areg_clk",
				      "ipe_1_axi_clk",
				      "ipe_1_clk",
				      "ipe_1_clk_src";
			clock-rates = <0 0 0 0 404000000>,
				      <0 0 0 0 480000000>,
				      <0 0 0 0 538000000>,
				      <0 0 0 0 600000000>;
			clock-cntl-level = "svs", "svs_l1", "nominal",
					   "turbo";
			power-domains = <&clock_camcc IPE_1_GDSC>;
			qcom,skip-probe-power-domain-cycle;
			src-clock-name = "ipe_1_clk_src";
			operating-points-v2 = <&cam_ipe_opp_table>;
			clock-control-debugfs = "true";
			status = "okay";
		};

		cam_bps: qcom,bps {
			compatible = "qcom,cam-bps";
			reg = <0 0x0ac6f000 0 0x3000>;
			reg-names = "bps_top";
			reg-cam-base = <0x6f000>;
			cell-index = <0>;
			clocks = <&clock_camcc CAM_CC_BPS_AHB_CLK>,
				 <&clock_camcc CAM_CC_BPS_AREG_CLK>,
				 <&clock_camcc CAM_CC_BPS_AXI_CLK>,
				 <&clock_camcc CAM_CC_BPS_CLK>,
				 <&clock_camcc CAM_CC_BPS_CLK_SRC>;
			clock-names = "bps_ahb_clk",
				      "bps_areg_clk",
				      "bps_axi_clk",
				      "bps_clk",
				      "bps_clk_src";
			clock-rates = <0 0 0 0 404000000>,
				      <0 0 0 0 480000000>,
				      <0 0 0 0 600000000>,
				      <0 0 0 0 600000000>;
			clock-cntl-level = "svs", "svs_l1", "nominal", "turbo";
			power-domains = <&clock_camcc BPS_GDSC>;
			qcom,skip-probe-power-domain-cycle;
			src-clock-name = "bps_clk_src";
			operating-points-v2 = <&cam_bps_opp_table>;
			clock-control-debugfs = "true";
			status = "okay";

			cam_bps_opp_table: opp-table {
				compatible = "operating-points-v2";

				opp-404000000 {
					opp-hz = /bits/ 64 <404000000>;
				};

				opp-480000000 {
					opp-hz = /bits/ 64 <480000000>;
				};

				opp-600000000 {
					opp-hz = /bits/ 64 <600000000>;
				};
			};
		};

		cam_req_mgr: cam-req-mgr {
			compatible = "qcom,cam-req-mgr";
			status = "okay";
		};
	};
};

&pm8998_gpios {
	camera_rear_dvdd_en_default: camera-rear-dvdd-en-state {
		pins = "gpio12";
		function = "normal";
		power-source = <0>;
		bias-pull-down;
		drive-push-pull;
		qcom,drive-strength = <PMIC_GPIO_STRENGTH_HIGH>;
		output-low;
	};
};

&tlmm {
	cam_sensor_mclk0_active: cam-sensor-mclk0-active-state {
		pins = "gpio13";
		function = "cam_mclk";
		bias-disable;
		drive-strength = <2>;
	};

	cam_sensor_mclk0_suspend: cam-sensor-mclk0-suspend-state {
		pins = "gpio13";
		function = "cam_mclk";
		bias-pull-down;
		drive-strength = <8>;
	};

	cam_sensor_mclk1_active: cam-sensor-mclk1-active-state {
		pins = "gpio14";
		function = "cam_mclk";
		bias-disable;
		drive-strength = <2>;
	};

	cam_sensor_mclk1_suspend: cam-sensor-mclk1-suspend-state {
		pins = "gpio14";
		function = "cam_mclk";
		bias-pull-down;
		drive-strength = <8>;
	};

	cam_sensor_mclk2_active: cam-sensor-mclk2-active-state {
		pins = "gpio15";
		function = "cam_mclk";
		bias-disable;
		drive-strength = <2>;
	};

	cam_sensor_mclk2_suspend: cam-sensor-mclk2-suspend-state {
		pins = "gpio15";
		function = "cam_mclk";
		bias-pull-down;
		drive-strength = <8>;
	};

	cam_sensor_reset0_active: cam-sensor-reset0-active-state {
		pins = "gpio9";
		function = "gpio";
		bias-disable;
		drive-strength = <2>;
	};

	cam_sensor_reset0_suspend: cam-sensor-reset0-suspend-state {
		pins = "gpio9";
		function = "gpio";
		bias-pull-down;
		drive-strength = <2>;
		output-low;
	};

	cam_sensor_reset1_active: cam-sensor-reset1-active-state {
		pins = "gpio7";
		function = "gpio";
		bias-disable;
		drive-strength = <2>;
	};

	cam_sensor_reset1_suspend: cam-sensor-reset1-suspend-state {
		pins = "gpio7";
		function = "gpio";
		bias-pull-down;
		drive-strength = <2>;
		output-low;
	};

	cam_sensor_reset2_active: cam-sensor-reset2-active-state {
		pins = "gpio12";
		function = "gpio";
		bias-disable;
		drive-strength = <2>;
	};

	cam_sensor_reset2_suspend: cam-sensor-reset2-suspend-state {
		pins = "gpio12";
		function = "gpio";
		bias-pull-down;
		drive-strength = <2>;
		output-low;
	};

	cam_sensor_front_active: cam-sensor-front-active-state {
		pins = "gpio28";
		function = "gpio";
		bias-disable;
		drive-strength = <2>;
	};

	cam_sensor_front_suspend: cam-sensor-front-suspend-state {
		pins = "gpio28";
		function = "gpio";
		bias-pull-down;
		drive-strength = <2>;
		output-low;
	};

	cam_sensor_vana_active: cam-sensor-vana-active-state {
		pins = "gpio8";
		function = "gpio";
		bias-disable;
		drive-strength = <2>;
	};

	cam_sensor_vana_suspend: cam-sensor-vana-suspend-state {
		pins = "gpio8";
		function = "gpio";
		bias-disable;
		drive-strength = <2>;
		output-low;
	};
};

&vreg_lvs1a_1p8 {
	regulator-always-on;
};

&wifi {
	status = "okay";

	vdd-0.8-cx-mx-supply = <&vreg_l5a_0p8>;
	vdd-1.3-rfa-supply = <&vreg_l17a_1p3>;
	vdd-1.8-xo-supply = <&vreg_l7a_1p8>;
	vdd-3.3-ch0-supply = <&vreg_l25a_3p3>;
	vdd-3.3-ch1-supply = <&vreg_l23a_3p3>;

	qcom,snoc-host-cap-skip-quirk;
};
